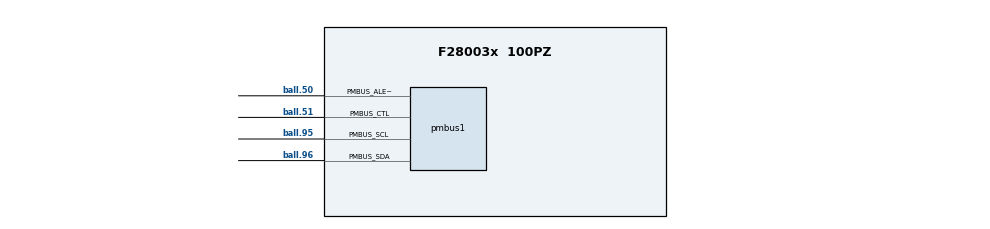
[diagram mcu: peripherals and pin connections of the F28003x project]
/**
 * @cliArgs --device "F28003x" --package "100PZ" --part "F28003x_100PZ" --product "C2000WARE@3.01.00.00"
 * @versions {"tool":"1.10.0+2163"}
 */

/**
 * Import the modules used in this configuration.
 */
const pmbus  = scripting.addModule("/driverlib/pmbus.js");
const pmbus1 = pmbus.addInstance();

/**
 * Write custom configuration values to the imported modules.
 */
pmbus1.$name                        = "myPMBUS0";
pmbus1.registerInterrupts           = true;
pmbus1.BaudRate                     = 20000000;
pmbus1.mode                         = "Target";
pmbus1.OwnAddress                   = 0x6A;
pmbus1.TargetAddress                = 0x1A;
pmbus1.configTarget                 = ["PMBUS_TARGET_AUTO_ACK_4_BYTES","PMBUS_TARGET_ENABLE_PEC_PROCESSING"];
pmbus1.enabledInterrupts            = ["PMBUS_INT_DATA_READY","PMBUS_INT_DATA_REQUEST","PMBUS_INT_EOM"];
pmbus1.enablePMBus                  = true;
pmbus1.useInterrupts                = true;
pmbus1.pmbus.$assign                = "PMBUSA";
pmbus1.pmbus.pmbus_alertPin.$assign = "ball.50";
pmbus1.pmbus.pmbus_ctlPin.$assign   = "ball.51";
pmbus1.pmbus.pmbus_sclPin.$assign   = "ball.95";
pmbus1.pmbus.pmbus_sdaPin.$assign   = "ball.96";
pmbus1.PMBusInt.enableInterrupt     = true;
pmbus1.PMBusInt.interruptHandler    = "pmbusIntHandler";
